AUTOSAR XML (schema 4-2-1)
package /RootP_IntDcm
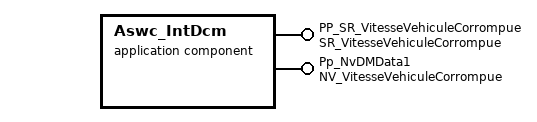
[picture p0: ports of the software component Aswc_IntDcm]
  application sw component type Aswc_IntDcm
    provide port PP_SR_VitesseVehiculeCorrompue: provided-interface=SR_VitesseVehiculeCorrompue
    provide port Pp_NvDMData1: provided-com-specs=[data1U32, data2U16], provided-interface=NV_VitesseVehiculeCorrompue
package /RootP_Composition
  composition sw component type Compo_VSM
    component Instance_ASWC_M741: type=ASWC_M741
